# PIC32CM5112SG00048 device description
Architecture: CORTEX-M23; Family: PIC32CM; Series: PIC32CMSG00
Registers are 32-bit, read-write, reset 0x0 unless marked. A register's access mark holds for its fields unless they carry their own. Offsets are from the block's base; [hi:lo] are bit positions; {n}, {i} and the like mark numbered series; 'fields as' and 'values as' point back to an identical list; <NAME> marks a mode.

## TCC — Timer Counter for Control Applications
Instances: TCC{n} {0x44810000+0x2000*n} (n=0..3), TCC4 0x44824000, TCC5 0x44826000, TCC6 0x44828000
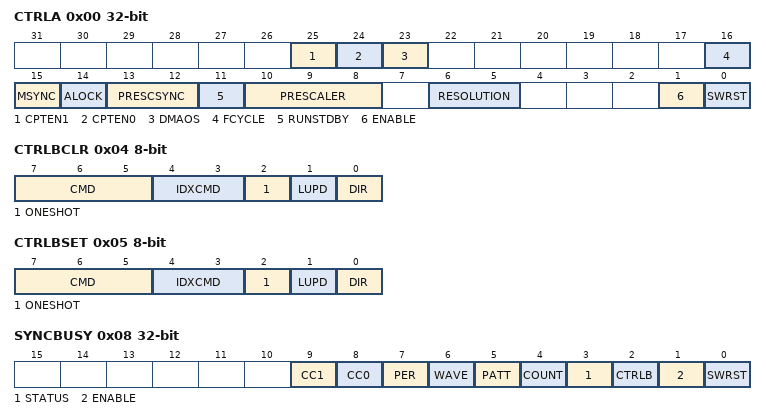
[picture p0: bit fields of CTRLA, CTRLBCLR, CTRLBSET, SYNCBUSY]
0x00 CTRLA (WSYNC) — Control A
  [25] CPTEN1 — Capture Channel 1 Enable
  [24] CPTEN0 — Capture Channel 0 Enable
  [23] DMAOS — DMA One-shot Trigger Mode
  [16] FCYCLE — Full Cycle
  [15] MSYNC — Master Synchronization (only for TCC Slave Instance)
  [14] ALOCK — Auto Lock
  [13:12] PRESCSYNC — Prescaler and Counter Synchronization Selection
    0=GCLK (Reload or reset counter on next GCLK); 1=PRESC (Reload or reset counter on next prescaler clock); 2=RESYNC (Reload or reset counter on next GCLK and reset prescaler counter)
  [11] RUNSTDBY — Run in Standby
  [10:8] PRESCALER
    0=DIV1 (No division); 1=DIV2 (Divide by 2); 2=DIV4 (Divide by 4); 3=DIV8 (Divide by 8); 4=DIV16 (Divide by 16); 5=DIV64 (Divide by 64); 6=DIV256 (Divide by 256); 7=DIV1024 (Divide by 1024)
  [6:5] RESOLUTION — Enhanced Resolution
    0=NONE (Dithering is disabled); 1=DITH4 (Dithering is done every 16 PWM frames); 2=DITH5 (Dithering is done every 32 PWM frames); 3=DITH6 (Dithering is done every 64 PWM frames)
  [1] ENABLE
  [0] SWRST — Software Reset
0x04 CTRLBCLR 8-bit (atomic clear) (RWSYNC) — Control B Clear
  [7:5] CMD — TCC Command
    0=NONE (No action); 1=RETRIGGER (Clear start, restart or retrigger); 2=STOP (Force stop); 3=UPDATE (Force update or double buffered registers); 4=READSYNC (Force COUNT read synchronization); 5=DMAOS (One-shot DMA trigger)
  [4:3] IDXCMD — Ramp Index Command
    0=DISABLE (Command disabled: Index toggles between cycles A and B); 1=SET (Set index: cycle B will be forced in the next cycle); 2=CLEAR (Clear index: cycle A will be forced in the next cycle); 3=HOLD (Hold index: the next cycle will be the same as the current cycle)
  [2] ONESHOT
  [1] LUPD — Lock Update
  [0] DIR — Counter Direction
0x05 CTRLBSET 8-bit (atomic set) (RWSYNC) — Control B Set
  fields as CTRLBCLR
0x08 SYNCBUSY ro — Synchronization Busy
  [9] CC1 — Compare Channel 1 Busy
  [8] CC0 — Compare Channel 0 Busy
  [7] PER — Period Busy
  [6] WAVE — Wave Busy
  [5] PATT — Pattern Busy
  [4] COUNT — Count Busy
  [3] STATUS — Status Busy
  [2] CTRLB — Ctrlb Busy
  [1] ENABLE — Enable Busy
  [0] SWRST — Swrst Busy
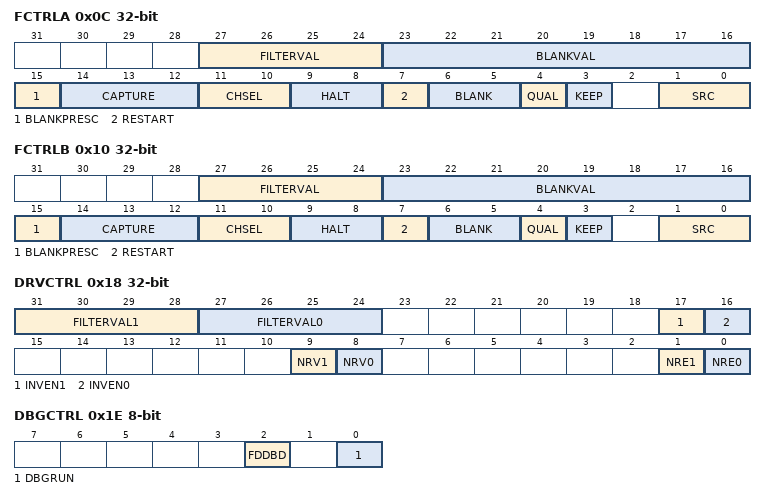
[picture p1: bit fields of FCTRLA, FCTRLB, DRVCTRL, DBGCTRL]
0x0C FCTRLA — Recoverable Fault A Configuration
  [27:24] FILTERVAL — Fault A Filter Value
  [23:16] BLANKVAL — Fault A Blanking Time
  [15] BLANKPRESC — Fault A Blanking Prescaler
  [14:12] CAPTURE — Fault A Capture Action
    0=DISABLE (No capture); 1=CAPT (Capture on fault); 2=CAPTMIN (Minimum capture); 3=CAPTMAX (Maximum capture); 4=LOCMIN (Minimum local detection); 5=LOCMAX (Maximum local detection); 6=DERIV0 (Minimum and maximum local detection); 7=CAPTMARK (Capture with ramp index as MSB value)
  [11:10] CHSEL — Fault A Capture Channel
    {v}=CC{v} (Capture value stored in channel {v}) (v=0..3)
  [9:8] HALT — Fault A Halt Mode
    0=DISABLE (Halt action disabled); 1=HW (Hardware halt action); 2=SW (Software halt action); 3=NR (Non-recoverable fault)
  [7] RESTART — Fault A Restart
  [6:5] BLANK — Fault A Blanking Mode
    0=START (Blanking applied from start of the ramp); 1=RISE (Blanking applied from rising edge of the output waveform); 2=FALL (Blanking applied from falling edge of the output waveform); 3=BOTH (Blanking applied from each toggle of the output waveform)
  [4] QUAL — Fault A Qualification
  [3] KEEP — Fault A Keeper
  [1:0] SRC — Fault A Source
    0=DISABLE (Fault input disabled); 1=ENABLE (MCEx (x=0,1) event input); 2=INVERT (Inverted MCEx (x=0,1) event input); 3=ALTFAULT (Alternate fault (A or B) state at the end of the previous period)
0x10 FCTRLB — Recoverable Fault B Configuration
  [27:24] FILTERVAL — Fault B Filter Value
  [23:16] BLANKVAL — Fault B Blanking Time
  [15] BLANKPRESC — Fault B Blanking Prescaler
  [14:12] CAPTURE — Fault B Capture Action
    values as FCTRLA.CAPTURE
  [11:10] CHSEL — Fault B Capture Channel
    {v}=CC{v} (Capture value stored in channel {v}) (v=0..3)
  [9:8] HALT — Fault B Halt Mode
    values as FCTRLA.HALT
  [7] RESTART — Fault B Restart
  [6:5] BLANK — Fault B Blanking Mode
    values as FCTRLA.BLANK
  [4] QUAL — Fault B Qualification
  [3] KEEP — Fault B Keeper
  [1:0] SRC — Fault B Source
    values as FCTRLA.SRC
0x18 DRVCTRL — Driver Control
  [31:28] FILTERVAL1 — Non-Recoverable Fault Input 1 Filter Value
  [27:24] FILTERVAL0 — Non-Recoverable Fault Input 0 Filter Value
  [17] INVEN1 — Output Waveform 1 Inversion
  [16] INVEN0 — Output Waveform 0 Inversion
  [9] NRV1 — Non-Recoverable State 1 Output Value
  [8] NRV0 — Non-Recoverable State 0 Output Value
  [1] NRE1 — Non-Recoverable State 1 Output Enable
  [0] NRE0 — Non-Recoverable State 0 Output Enable
0x1E DBGCTRL 8-bit — Debug Control
  [2] FDDBD — Fault Detection on Debug Break Detection
  [0] DBGRUN — Debug Running Mode
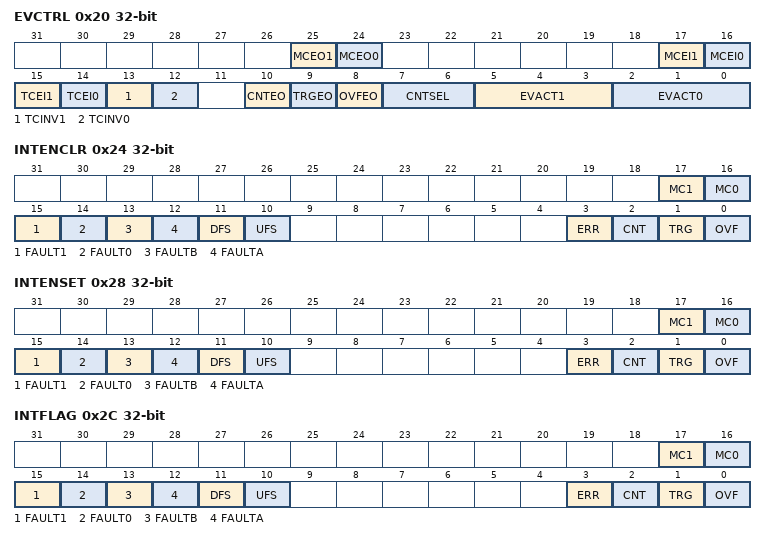
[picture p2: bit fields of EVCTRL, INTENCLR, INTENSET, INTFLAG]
0x20 EVCTRL — Event Control
  [25] MCEO1 — Match or Capture Channel 1 Event Output Enable
  [24] MCEO0 — Match or Capture Channel 0 Event Output Enable
  [17] MCEI1 — Match or Capture Channel 1 Event Input Enable
  [16] MCEI0 — Match or Capture Channel 0 Event Input Enable
  [15] TCEI1 — Timer/counter Event 1 Input Enable
  [14] TCEI0 — Timer/counter Event 0 Input Enable
  [13] TCINV1 — Inverted Event 1 Input Enable
  [12] TCINV0 — Inverted Event 0 Input Enable
  [10] CNTEO — Timer/counter Output Event Enable
  [9] TRGEO — Retrigger Output Event Enable
  [8] OVFEO — Overflow/Underflow Output Event Enable
  [7:6] CNTSEL — Timer/counter Output Event Mode
    0=START (An interrupt/event is generated when a new counter cycle starts); 1=END (An interrupt/event is generated when a counter cycle ends); 3=BOUNDARY (An interrupt/event is generated when a new counter cycle starts or a counter cycle ends)
  [5:3] EVACT1 — Timer/counter Input Event1 Action
    0=OFF (Event action disabled); 1=RETRIGGER (Re-trigger counter on event); 2=DIR (Direction control); 3=STOP (Stop counter on event); 4=DEC (Decrement counter on event); 6=PWP (Period capture value in CC1 register, pulse width capture value in CC0 register); 7=FAULT (Non-recoverable fault)
  [2:0] EVACT0 — Timer/counter Input Event0 Action
    0=OFF (Event action disabled); 1=RETRIGGER (Start, restart or re-trigger counter on event); 2=COUNTEV (Count on event); 3=START (Start counter on event); 4=INC (Increment counter on event); 5=COUNT (Count on active state of asynchronous event); 6=STAMP (Stamp capture); 7=FAULT (Non-recoverable fault)
0x24 INTENCLR (atomic clear) — Interrupt Enable Clear
  [17] MC1 — Match or Capture Channel 1 Interrupt Enable
  [16] MC0 — Match or Capture Channel 0 Interrupt Enable
  [15] FAULT1 — Non-Recoverable Fault 1 Interrupt Enable
  [14] FAULT0 — Non-Recoverable Fault 0 Interrupt Enable
  [13] FAULTB — Recoverable Fault B Interrupt Enable
  [12] FAULTA — Recoverable Fault A Interrupt Enable
  [11] DFS — Non-Recoverable Debug Fault Interrupt Enable
  [10] UFS — Non-Recoverable Update Fault Interrupt Enable
  [3] ERR — Error Interrupt Enable
  [2] CNT — Counter Interrupt Enable
  [1] TRG — Retrigger Interrupt Enable
  [0] OVF — Overflow Interrupt Enable
0x28 INTENSET (atomic set) — Interrupt Enable Set
  fields as INTENCLR
0x2C INTFLAG (atomic clear) — Interrupt Flag Status and Clear
  [17] MC1 — Match or Capture 1
  [16] MC0 — Match or Capture 0
  [15] FAULT1 — Non-Recoverable Fault 1
  [14] FAULT0 — Non-Recoverable Fault 0
  [13] FAULTB — Recoverable Fault B
  [12] FAULTA — Recoverable Fault A
  [11] DFS — Non-Recoverable Debug Fault
  [10] UFS — Non-Recoverable Update Fault
  [3] ERR — Error
  [2] CNT — Counter
  [1] TRG — Retrigger
  [0] OVF — Overflow
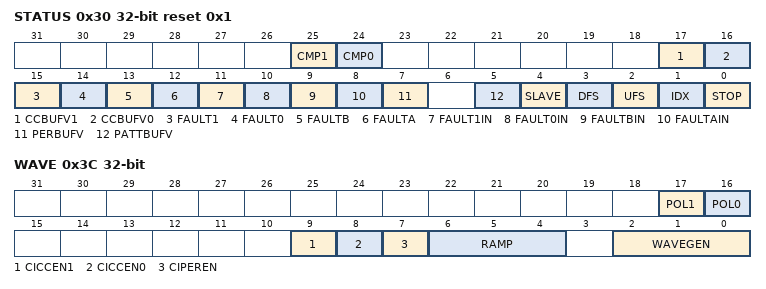
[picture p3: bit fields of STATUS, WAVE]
0x30 STATUS reset 0x1 (RWSYNC)
  [25] CMP1 — Compare Channel 1 Value
  [24] CMP0 — Compare Channel 0 Value
  [17] CCBUFV1 — Compare Channel 1 Buffer Valid
  [16] CCBUFV0 — Compare Channel 0 Buffer Valid
  [15] FAULT1 — Non-Recoverable Fault 1 State
  [14] FAULT0 — Non-Recoverable Fault 0 State
  [13] FAULTB — Recoverable Fault B State
  [12] FAULTA — Recoverable Fault A State
  [11] FAULT1IN — Non-Recoverable Fault1 Input
  [10] FAULT0IN — Non-Recoverable Fault0 Input
  [9] FAULTBIN — Recoverable Fault B Input
  [8] FAULTAIN — Recoverable Fault A Input
  [7] PERBUFV — Period Buffer Valid
  [5] PATTBUFV — Pattern Buffer Valid
  [4] SLAVE
  [3] DFS — Non-Recoverable Debug Fault State
  [2] UFS — Non-recoverable Update Fault State
  [1] IDX — Ramp
  [0] STOP
0x34 COUNT (RWSYNC) (modes: DEFAULT when TCC.CTRLA.RESOLUTION=0; DITH4 when TCC.CTRLA.RESOLUTION=1; DITH5 when TCC.CTRLA.RESOLUTION=2; DITH6 when TCC.CTRLA.RESOLUTION=3)
  [15:0] COUNT <DEFAULT> — Counter Value
  [15:4] COUNT <DITH4> — Counter Value
  [15:5] COUNT <DITH5> — Counter Value
  [15:6] COUNT <DITH6> — Counter Value
0x3C WAVE (WSYNC) — Waveform Control
  [17] POL1 — Channel 1 Polarity
  [16] POL0 — Channel 0 Polarity
  [9] CICCEN1 — Circular Channel 1 Enable
  [8] CICCEN0 — Circular Channel 0 Enable
  [7] CIPEREN — Circular period Enable
  [6:4] RAMP — Ramp Mode
    0=RAMP1 operation; 1=RAMP2A (Alternative RAMP2 operation); 2=RAMP2 operation; 3=RAMP2C (Critical RAMP2 operation); 4=RAMP2CS (Critical Swapped RAMP2 operation)
  [2:0] WAVEGEN — Waveform Generation
    0=NFRQ (Normal frequency); 1=MFRQ (Match frequency); 2=NPWM (Normal PWM); 3=DPWM (Dual compare PWM); 4=DSCRITICAL (Dual-slope critical); 5=DSBOTTOM (Dual-slope with interrupt/event condition when COUNT reaches ZERO); 6=DSBOTH (Dual-slope with interrupt/event condition when COUNT reaches ZERO or TOP); 7=DSTOP (Dual-slope with interrupt/event condition when COUNT reaches TOP)
0x40 PER reset 0xFFFF (WSYNC) (modes: DEFAULT when TCC.CTRLA.RESOLUTION=0; DITH4 when TCC.CTRLA.RESOLUTION=1; DITH5 when TCC.CTRLA.RESOLUTION=2; DITH6 when TCC.CTRLA.RESOLUTION=3) — Period
  [15:0] PER <DEFAULT> — Period Value
  [15:4] PER <DITH4> — Period Value
  [3:0] DITHER <DITH4> — Dithering Cycle Number
  [15:5] PER <DITH5> — Period Value
  [4:0] DITHER <DITH5> — Dithering Cycle Number
  [15:6] PER <DITH6> — Period Value
  [5:0] DITHER <DITH6> — Dithering Cycle Number
{0x44+4i} CC[{i}] (i=0..1) (RWSYNC) (modes: DEFAULT when TCC.CTRLA.RESOLUTION=0; DITH4 when TCC.CTRLA.RESOLUTION=1; DITH5 when TCC.CTRLA.RESOLUTION=2; DITH6 when TCC.CTRLA.RESOLUTION=3) — Compare and Capture
  [15:0] CC <DEFAULT> — Channel Compare/Capture Value
  [15:4] CC <DITH4> — Channel Compare/Capture Value
  [3:0] DITHER <DITH4> — Dithering Cycle Number
  [15:5] CC <DITH5> — Channel Compare/Capture Value
  [4:0] DITHER <DITH5> — Dithering Cycle Number
  [15:6] CC <DITH6> — Channel Compare/Capture Value
  [5:0] DITHER <DITH6> — Dithering Cycle Number
0x6C PERBUF reset 0xFFFF (WSYNC) (modes: DEFAULT when TCC.CTRLA.RESOLUTION=0; DITH4 when TCC.CTRLA.RESOLUTION=1; DITH5 when TCC.CTRLA.RESOLUTION=2; DITH6 when TCC.CTRLA.RESOLUTION=3) — Period Buffer
  [15:0] PERBUF <DEFAULT> — Period Buffer Value
  [15:4] PERBUF <DITH4> — Period Buffer Value
  [3:0] DITHERBUF <DITH4> — Dithering Buffer Cycle Number
  [15:5] PERBUF <DITH5> — Period Buffer Value
  [4:0] DITHERBUF <DITH5> — Dithering Buffer Cycle Number
  [15:6] PERBUF <DITH6> — Period Buffer Value
  [5:0] DITHERBUF <DITH6> — Dithering Buffer Cycle Number
{0x70+4i} CCBUF[{i}] (i=0..1) (WSYNC) (modes: DEFAULT when TCC.CTRLA.RESOLUTION=0; DITH4 when TCC.CTRLA.RESOLUTION=1; DITH5 when TCC.CTRLA.RESOLUTION=2; DITH6 when TCC.CTRLA.RESOLUTION=3) — Compare and Capture Buffer
  [15:0] CCBUF <DEFAULT> — Channel Compare/Capture Buffer Value
  [15:4] CCBUF <DITH4> — Dithering Buffer Cycle Number
  [3:0] DITHERBUF <DITH4> — Channel Compare/Capture Buffer Value
  [15:5] CCBUF <DITH5> — Channel Compare/Capture Buffer Value
  [4:0] DITHERBUF <DITH5> — Dithering Buffer Cycle Number
  [15:6] CCBUF <DITH6> — Channel Compare/Capture Buffer Value
  [5:0] DITHERBUF <DITH6> — Dithering Buffer Cycle Number
